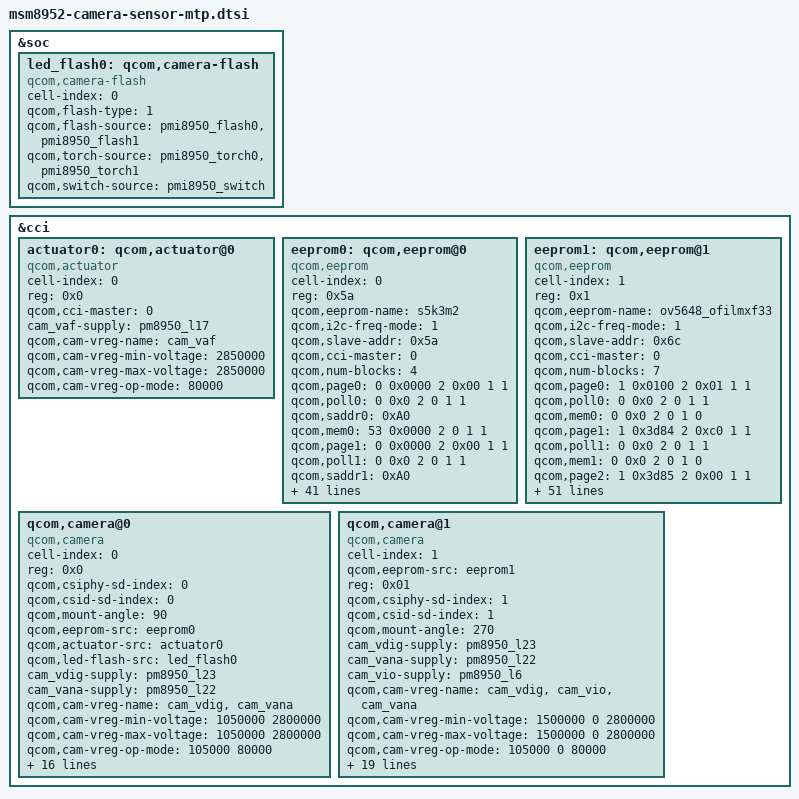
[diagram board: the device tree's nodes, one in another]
/*
 * Copyright (c) 2015, The Linux Foundation. All rights reserved.
 *
 * This program is free software; you can redistribute it and/or modify
 * it under the terms of the GNU General Public License version 2 and
 * only version 2 as published by the Free Software Foundation.
 *
 * This program is distributed in the hope that it will be useful,
 * but WITHOUT ANY WARRANTY; without even the implied warranty of
 * MERCHANTABILITY or FITNESS FOR A PARTICULAR PURPOSE.  See the
 * GNU General Public License for more details.
 */

&soc {
	led_flash0: qcom,camera-flash {
		cell-index = <0>;
		compatible = "qcom,camera-flash";
		qcom,flash-type = <1>;
		qcom,flash-source = <&pmi8950_flash0 &pmi8950_flash1>;
		qcom,torch-source = <&pmi8950_torch0 &pmi8950_torch1>;
		qcom,switch-source = <&pmi8950_switch>;
	};
};

&cci {
	actuator0: qcom,actuator@0 {
		cell-index = <0>;
		reg = <0x0>;
		compatible = "qcom,actuator";
		qcom,cci-master = <0>;
		cam_vaf-supply = <&pm8950_l17>;
		qcom,cam-vreg-name = "cam_vaf";
		qcom,cam-vreg-min-voltage = <2850000>;
		qcom,cam-vreg-max-voltage = <2850000>;
		qcom,cam-vreg-op-mode = <80000>;
	};

	eeprom0: qcom,eeprom@0 {
		cell-index = <0>;
		reg = <0x5a>;
		qcom,eeprom-name = "s5k3m2";
		compatible = "qcom,eeprom";
		qcom,i2c-freq-mode = <1>;
		qcom,slave-addr = <0x5a>;
		qcom,cci-master = <0>;
		qcom,num-blocks = <4>;

		qcom,page0 = <0 0x0000 2 0x00 1 1>;
		qcom,poll0 = <0 0x0 2 0 1 1>;
		qcom,saddr0 =<0xA0>;
		qcom,mem0 = <53 0x0000 2 0 1 1>;

		qcom,page1 = <0 0x0000 2 0x00 1 1>;
		qcom,poll1 = <0 0x0 2 0 1 1>;
		qcom,saddr1 =<0xA0>;
		qcom,mem1 = <1280 0x0200 2 0 1 1>;

		qcom,page2 = <0 0x0000 2 0x00 1 1>;
		qcom,poll2 = <0 0x0 2 0 1 1>;
		qcom,saddr2 =<0xA0>;
		qcom,mem2 = <530 0x700 2 0 1 1>;

		qcom,page3 = <0 0x0000 2 0x00 1 1>;
		qcom,poll3 = <0 0x0 2 0 1 1>;
		qcom,saddr3 =<0xA0>;
		qcom,mem3 = <6 0xB06 2 0 1 1>;

		cam_vdig-supply = <&pm8950_l23>;
		cam_vana-supply = <&pm8950_l22>;
		cam_vaf-supply = <&pm8950_l17>;
		qcom,cam-vreg-name = "cam_vdig", "cam_vana",
							"cam_vaf";
		qcom,cam-vreg-min-voltage = <1050000 2800000 2850000>;
		qcom,cam-vreg-max-voltage = <1050000 2800000 2850000>;
		qcom,cam-vreg-op-mode = <105000 80000 100000>;
		pinctrl-names = "cam_default", "cam_suspend";
		pinctrl-0 = <&cam_sensor_mclk0_default
				&cam_sensor_rear_default>;
		pinctrl-1 = <&cam_sensor_mclk0_sleep &cam_sensor_rear_sleep>;
		gpios = <&msm_gpio 26 0>,
			<&msm_gpio 36 0>,
			<&msm_gpio 59 0>;
		qcom,gpio-reset = <1>;
		qcom,gpio-vio = <2>;
		qcom,gpio-req-tbl-num = <0 1 2>;
		qcom,gpio-req-tbl-flags = <1 0 0>;
		qcom,gpio-req-tbl-label = "CAMIF_MCLK0",
			"CAM_RESET0",
			"CAM_VIO0";
		qcom,cam-power-seq-type = "sensor_gpio", "sensor_vreg", "sensor_gpio",
		    "sensor_vreg", "sensor_vreg", "sensor_clk",
			"sensor_gpio";
		qcom,cam-power-seq-val = "sensor_gpio_reset", "cam_vana", "sensor_gpio_vio", "cam_vdig", 
			"cam_vaf", "sensor_cam_mclk", "sensor_gpio_reset";
		qcom,cam-power-seq-cfg-val = <0 1 1 1 1 24000000 1>;
		qcom,cam-power-seq-delay =   <1 0 0 0 1 1 10>;
		status = "ok";
		clocks = <&clock_gcc clk_mclk0_clk_src>,
				<&clock_gcc clk_gcc_camss_mclk0_clk>;
		clock-names = "cam_src_clk", "cam_clk";
	};
    eeprom1: qcom,eeprom@1 {
        cell-index = <1>;
        reg = <0x1>;
        qcom,eeprom-name = "ov5648_ofilmxf33";
        qcom,i2c-freq-mode = <1>;
        compatible = "qcom,eeprom";
        qcom,slave-addr = <0x6c>;
        qcom,cci-master = <0>;
        qcom,num-blocks = <7>;

		qcom,page0 = <1 0x0100 2 0x01 1 1>;
		qcom,poll0 = <0 0x0 2 0 1 1>;
		qcom,mem0 = <0 0x0 2 0 1 0>;
		qcom,page1 = <1 0x3d84 2 0xc0 1 1>;
		qcom,poll1 = <0 0x0 2 0 1 1>;
		qcom,mem1 = <0 0x0 2 0 1 0>;
		qcom,page2 = <1 0x3d85 2 0x00 1 1>;
		qcom,poll2 = <0 0x0 2 0 1 1>;
		qcom,mem2 = <0 0x0 2 0 1 0>;
		qcom,page3 = <1 0x3d86 2 0x0f 1 1>;
		qcom,pageen3 = <1 0x3d81 2 0x01 1 10>;
		qcom,poll3 = <0 0x0 2 0 1 1>;
		qcom,mem3 = <16 0x3d00 2 0 1 0>;
		qcom,page4 = <1 0x3d84 2 0xc0 1 1>;
		qcom,poll4 = <0 0x0 2 0 1 1>;
		qcom,mem4 = <0 0x0 2 0 1 0>;
		qcom,page5 = <1 0x3d85 2 0x10 1 1>;
		qcom,poll5 = <0 0x0 2 0 1 1>;
		qcom,mem5 = <0 0x0 2 0 1 0>;
		qcom,page6 = <1 0x3d86 2 0x1f 1 1>;
		qcom,pageen6 = <1 0x3d81 2 0x01 1 10>;
		qcom,poll6 = <0 0x0 2 0 1 1>;
		qcom,mem6 = <16 0x3d00 2 0 1 0>;
        
        cam_vdig-supply = <&pm8950_l23>;
		cam_vana-supply = <&pm8950_l22>;
		cam_vio-supply = <&pm8950_l6>;
		qcom,cam-vreg-name = "cam_vdig", "cam_vio", "cam_vana";
		qcom,cam-vreg-min-voltage = <1500000 0 2800000>;
		qcom,cam-vreg-max-voltage = <1500000 0 2800000>;
		qcom,cam-vreg-op-mode = <105000 0 80000>;
		qcom,gpio-no-mux = <0>;
		pinctrl-names = "cam_default", "cam_suspend";
		pinctrl-0 = <&cam_sensor_mclk2_default &cam_sensor_front1_default>;
		pinctrl-1 = <&cam_sensor_mclk2_sleep &cam_sensor_front1_sleep>;
		gpios = <&msm_gpio 28 0>,
			<&msm_gpio 40 0>,
			<&msm_gpio 39 0>,
			<&msm_gpio 59 0>;
		qcom,gpio-reset = <1>;
		qcom,gpio-standby = <2>;
		qcom,gpio-vio = <3>;
		qcom,gpio-req-tbl-num = <0 1 2 3>;
		qcom,gpio-req-tbl-flags = <1 0 0 0>;
		qcom,gpio-req-tbl-label = "CAMIF_MCLK2",
					  "CAM_RESET2",
					  "CAM_STANDBY2",
					  "CAM_VIO2";
        qcom,cam-power-seq-type = "sensor_gpio", "sensor_gpio", "sensor_vreg", "sensor_gpio", "sensor_vreg", "sensor_vreg",
        "sensor_gpio", "sensor_gpio" , "sensor_clk";
        qcom,cam-power-seq-val = "sensor_gpio_standby", "sensor_gpio_reset", "cam_vio", "sensor_gpio_vio", "cam_vana", "cam_vdig", 
        "sensor_gpio_standby", "sensor_gpio_reset", "sensor_cam_mclk";
        qcom,cam-power-seq-cfg-val = <0 0 1 1 1 1 1 1 24000000>;
        qcom,cam-power-seq-delay =   <1 1 0 0 0 5 1 10 1>;
        status = "ok";
        clocks = <&clock_gcc clk_mclk2_clk_src>,
        <&clock_gcc clk_gcc_camss_mclk2_clk>;
        clock-names = "cam_src_clk", "cam_clk";
    };
	qcom,camera@0 {
		cell-index = <0>;
		compatible = "qcom,camera";
		reg = <0x0>;
		qcom,csiphy-sd-index = <0>;
		qcom,csid-sd-index = <0>;
		qcom,mount-angle = <90>;
		qcom,eeprom-src = <&eeprom0>;
		qcom,actuator-src = <&actuator0>;
		qcom,led-flash-src = <&led_flash0>;
		cam_vdig-supply = <&pm8950_l23>;
		cam_vana-supply = <&pm8950_l22>;
		qcom,cam-vreg-name = "cam_vdig", "cam_vana";
		qcom,cam-vreg-min-voltage = <1050000 2800000>;
		qcom,cam-vreg-max-voltage = <1050000 2800000>;
		qcom,cam-vreg-op-mode = <105000 80000>;
		pinctrl-names = "cam_default", "cam_suspend";
		pinctrl-0 = <&cam_sensor_mclk0_default
				&cam_sensor_rear_default>;
		pinctrl-1 = <&cam_sensor_mclk0_sleep &cam_sensor_rear_sleep>;
		gpios = <&msm_gpio 26 0>,
			<&msm_gpio 36 0>,
			<&msm_gpio 59 0>;
		qcom,gpio-reset = <1>;
		qcom,gpio-vio = <2>;
		qcom,gpio-req-tbl-num = <0 1 2>;
		qcom,gpio-req-tbl-flags = <1 0 0>;
		qcom,gpio-req-tbl-label = "CAMIF_MCLK0",
			"CAM_RESET0",
			"CAM_VIO0";
		qcom,sensor-position = <0>;
		qcom,sensor-mode = <0>;
		qcom,cci-master = <0>;
		status = "ok";
		clocks = <&clock_gcc clk_mclk0_clk_src>,
				<&clock_gcc clk_gcc_camss_mclk0_clk>;
		clock-names = "cam_src_clk", "cam_clk";
	};

	qcom,camera@1 {
		cell-index = <1>;
		compatible = "qcom,camera";
		qcom,eeprom-src = <&eeprom1>;
		reg = <0x01>;
		qcom,csiphy-sd-index = <1>;
		qcom,csid-sd-index = <1>;
		qcom,mount-angle = <270>;
		cam_vdig-supply = <&pm8950_l23>;
		cam_vana-supply = <&pm8950_l22>;
		cam_vio-supply = <&pm8950_l6>;
		qcom,cam-vreg-name = "cam_vdig", "cam_vio", "cam_vana";
		qcom,cam-vreg-min-voltage = <1500000 0 2800000>;
		qcom,cam-vreg-max-voltage = <1500000 0 2800000>;
		qcom,cam-vreg-op-mode = <105000 0 80000>;
		qcom,gpio-no-mux = <0>;
		pinctrl-names = "cam_default", "cam_suspend";
		pinctrl-0 = <&cam_sensor_mclk2_default &cam_sensor_front1_default>;
		pinctrl-1 = <&cam_sensor_mclk2_sleep &cam_sensor_front1_sleep>;
		gpios = <&msm_gpio 28 0>,
			<&msm_gpio 40 0>,
			<&msm_gpio 39 0>,
			<&msm_gpio 59 0>;
		qcom,gpio-reset = <1>;
		qcom,gpio-standby = <2>;
		qcom,gpio-vio = <3>;
		qcom,gpio-req-tbl-num = <0 1 2 3>;
		qcom,gpio-req-tbl-flags = <1 0 0 0>;
		qcom,gpio-req-tbl-label = "CAMIF_MCLK2",
					  "CAM_RESET2",
					  "CAM_STANDBY2",
					  "CAM_VIO2";
		qcom,sensor-position = <1>;
		qcom,sensor-mode = <0>;
		qcom,cci-master = <0>;
		status = "ok";
		clocks = <&clock_gcc clk_mclk2_clk_src>,
			<&clock_gcc clk_gcc_camss_mclk2_clk>;
		clock-names = "cam_src_clk", "cam_clk";
	};

};
